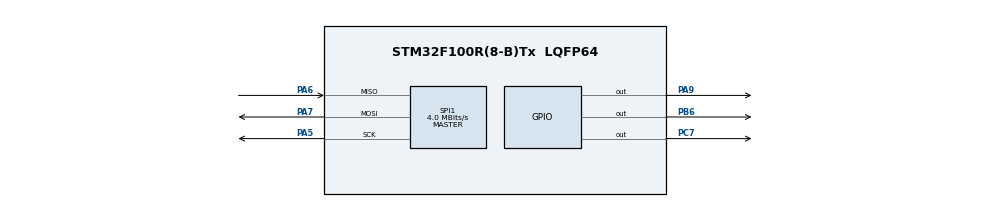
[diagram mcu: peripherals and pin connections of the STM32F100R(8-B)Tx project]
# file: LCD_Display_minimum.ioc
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Mcu.Family=STM32F1
Mcu.Name=STM32F100R(8-B)Tx
Mcu.Package=LQFP64
NVIC.PriorityGroup=NVIC_PRIORITYGROUP_4
PA13.Mode=Serial_Wire
PA13.Signal=SYS_JTMS-SWDIO
PA14.Mode=Serial_Wire
PA14.Signal=SYS_JTCK-SWCLK
PA5.Mode=Full_Duplex_Master
PA5.Signal=SPI1_SCK
PA6.Mode=Full_Duplex_Master
PA6.Signal=SPI1_MISO
PA7.Mode=Full_Duplex_Master
PA7.Signal=SPI1_MOSI
PA9.Signal=GPIO_Output
PB6.Signal=GPIO_Output
PC7.Signal=GPIO_Output
ProjectManager.HeapSize=0x200
ProjectManager.StackSize=0x400
ProjectManager.TargetToolchain=Makefile
RCC.APB1Freq_Value=8000000
RCC.APB2Freq_Value=8000000
SPI1.CalculateBaudRate=4.0 MBits/s
SPI1.Direction=SPI_DIRECTION_2LINES
SPI1.Mode=SPI_MODE_MASTER
SPI1.VirtualType=VM_MASTER
board=custom

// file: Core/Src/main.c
/* USER CODE BEGIN Header */
/**
 ******************************************************************************
 * @file           : main.c
 * @brief          : Main program body
 ******************************************************************************
 * @attention
 *
 * Copyright (c) 2025 STMicroelectronics.
 * All rights reserved.
 *
 * This software is licensed under terms that can be found in the LICENSE file
 * in the root directory of this software component.
 * If no LICENSE file comes with this software, it is provided AS-IS.
 *
 ******************************************************************************
 */
/* USER CODE END Header */
#include "main.h"

/* USER CODE BEGIN Includes */
#include "GFX_FUNCTIONS.h" /* USER CODE END Includes */
#include "ST7735.h"

/* USER CODE BEGIN PD */
// #define DCX_low()                                                              \
//   HAL_GPIO_WritePin(GPIOA, GPIO_PIN_9, GPIO_PIN_RESET) // command

// #define DCX_high()                                                             \
//   HAL_GPIO_WritePin(GPIOA, GPIO_PIN_9, GPIO_PIN_SET) // data/parameter

// #define SLEEP_OUT 0x11
// #define DISPLAY_ON 0x29

// // select at low level
// #define CSX_low() HAL_GPIO_WritePin(GPIOB, GPIO_PIN_6, GPIO_PIN_RESET)
// #define CSX_high() HAL_GPIO_WritePin(GPIOB, GPIO_PIN_6, GPIO_PIN_SET)

// // reset at low level
// #define RESX_low() HAL_GPIO_WritePin(GPIOC, GPIO_PIN_7, GPIO_PIN_RESET)
// #define RESX_high() HAL_GPIO_WritePin(GPIOC, GPIO_PIN_7, GPIO_PIN_SET)

// // pixel RGB565
// #define GREEN 0x07E0 // 0b0000011111100000
// #define RED 0xF100   // 0b1111100000000000
// #define BLUE 0x001F  // 0b0000000000011111

// #define COLMOD_CMD 0x3A
// #define COLMOD_16 0x55 // 16bits pro pixel

// #define RAMWR_CMD 0x2C // instruction before pixel data is sent

// #define MADCTL_CMD 0x36
// #define MADCTL_PARAM 0x00

// #define RASET_CMD 0x2B
// #define CASET_CMD 0x2A
// #define RASET_PARAM_START 0x0000 // Startzeile
// #define RASET_PARAM_END 0x0083   // Endzeile = 131
// #define CASET_PARAM_START 0x0000 // Startspalte
// #define CASET_PARAM_END 0x00A1   // Endspalte = 161''''
/* USER CODE END PD */

SPI_HandleTypeDef hspi1;

void SystemClock_Config(void);
static void MX_GPIO_Init(void);
static void MX_SPI1_Init(void);

/* USER CODE BEGIN 0 */
// void send_command(uint8_t command) {
//   volatile HAL_StatusTypeDef status;
//   DCX_low();
//   status = HAL_SPI_Transmit(&hspi1, &command, 1, HAL_MAX_DELAY);
//   DCX_high(); // im asnchluss kommen parmater
// }

// void send_1byte_param(uint8_t param) {
//   volatile HAL_StatusTypeDef status;
//   status = HAL_SPI_Transmit(&hspi1, &param, 1, HAL_MAX_DELAY);
// }

// uint32_t drawPixle(uint16_t color) {
//   uint32_t i;
//   uint32_t pixel = 128 * 160;
//   // Pixeldata senden (2 Bytes, Big Endian!)
//   uint8_t data[] = {color >> 8, color & 0xFF};
//   for (i = 0; i < pixel; i++) {
//     HAL_SPI_Transmit(&hspi1, data, 2, HAL_MAX_DELAY);
//   }
//   return i;
// }

/* USER CODE END 0 */

int main(void) {

  /* MCU Configuration--------------------------------------------------------*/

  /* Reset of all peripherals, Initializes the Flash interface and the Systick.
   */
  HAL_Init();

  /* Configure the system clock */
  SystemClock_Config();

  /* Initialize all configured peripherals */
  MX_GPIO_Init();
  MX_SPI1_Init();
  /* USER CODE BEGIN 2 */
  // CSX_low();
  // RESX_low();
  // HAL_Delay(50);
  // RESX_high();
  // HAL_Delay(120);
  // send_command(SLEEP_OUT); // SLP_OUT
  // HAL_Delay(120);
  // send_command(COLMOD_CMD); // COLMOD
  // send_1byte_param(COLMOD_16);
  // send_command(DISPLAY_ON);
  // HAL_Delay(20);
  // CSX_low();
  // send_command(RAMWR_CMD);
  // drawPixle(RED);
  // CSX_high();
  ST7735_Init(0);
  fillScreen(GREEN);
  /* USER CODE END 2 */

  /* Infinite loop */
  while (1) {

  }
}

void SystemClock_Config(void) {
  RCC_OscInitTypeDef RCC_OscInitStruct = {0};
  RCC_ClkInitTypeDef RCC_ClkInitStruct = {0};

  /** Initializes the RCC Oscillators according to the specified parameters
   * in the RCC_OscInitTypeDef structure.
   */
  RCC_OscInitStruct.OscillatorType = RCC_OSCILLATORTYPE_HSI;
  RCC_OscInitStruct.HSIState = RCC_HSI_ON;
  RCC_OscInitStruct.HSICalibrationValue = RCC_HSICALIBRATION_DEFAULT;
  RCC_OscInitStruct.PLL.PLLState = RCC_PLL_NONE;
  if (HAL_RCC_OscConfig(&RCC_OscInitStruct) != HAL_OK) {
    Error_Handler();
  }

  /** Initializes the CPU, AHB and APB buses clocks
   */
  RCC_ClkInitStruct.ClockType = RCC_CLOCKTYPE_HCLK | RCC_CLOCKTYPE_SYSCLK |
                                RCC_CLOCKTYPE_PCLK1 | RCC_CLOCKTYPE_PCLK2;
  RCC_ClkInitStruct.SYSCLKSource = RCC_SYSCLKSOURCE_HSI;
  RCC_ClkInitStruct.AHBCLKDivider = RCC_SYSCLK_DIV1;
  RCC_ClkInitStruct.APB1CLKDivider = RCC_HCLK_DIV1;
  RCC_ClkInitStruct.APB2CLKDivider = RCC_HCLK_DIV1;

  if (HAL_RCC_ClockConfig(&RCC_ClkInitStruct, FLASH_LATENCY_0) != HAL_OK) {
    Error_Handler();
  }
}

static void MX_SPI1_Init(void) {

  /* SPI1 parameter configuration*/
  hspi1.Instance = SPI1;
  hspi1.Init.Mode = SPI_MODE_MASTER;
  hspi1.Init.Direction = SPI_DIRECTION_2LINES;
  hspi1.Init.DataSize = SPI_DATASIZE_8BIT;
  hspi1.Init.CLKPolarity = SPI_POLARITY_LOW;
  hspi1.Init.CLKPhase = SPI_PHASE_1EDGE;
  hspi1.Init.NSS = SPI_NSS_SOFT;
  hspi1.Init.BaudRatePrescaler = SPI_BAUDRATEPRESCALER_2;
  hspi1.Init.FirstBit = SPI_FIRSTBIT_MSB;
  hspi1.Init.TIMode = SPI_TIMODE_DISABLE;
  hspi1.Init.CRCCalculation = SPI_CRCCALCULATION_DISABLE;
  hspi1.Init.CRCPolynomial = 10;
  if (HAL_SPI_Init(&hspi1) != HAL_OK) {
    Error_Handler();
  }
}

static void MX_GPIO_Init(void) {
  GPIO_InitTypeDef GPIO_InitStruct = {0};

  /* GPIO Ports Clock Enable */
  __HAL_RCC_GPIOA_CLK_ENABLE();
  __HAL_RCC_GPIOC_CLK_ENABLE();
  __HAL_RCC_GPIOB_CLK_ENABLE();

  /*Configure GPIO pin Output Level */
  HAL_GPIO_WritePin(GPIOC, GPIO_PIN_7, GPIO_PIN_RESET);

  /*Configure GPIO pin Output Level */
  HAL_GPIO_WritePin(GPIOA, GPIO_PIN_9, GPIO_PIN_RESET);

  /*Configure GPIO pin Output Level */
  HAL_GPIO_WritePin(GPIOB, GPIO_PIN_6, GPIO_PIN_RESET);

  /*Configure GPIO pin : PC7 */
  GPIO_InitStruct.Pin = GPIO_PIN_7;
  GPIO_InitStruct.Mode = GPIO_MODE_OUTPUT_PP;
  GPIO_InitStruct.Pull = GPIO_NOPULL;
  GPIO_InitStruct.Speed = GPIO_SPEED_FREQ_LOW;
  HAL_GPIO_Init(GPIOC, &GPIO_InitStruct);

  /*Configure GPIO pin : PA9 */
  GPIO_InitStruct.Pin = GPIO_PIN_9;
  GPIO_InitStruct.Mode = GPIO_MODE_OUTPUT_PP;
  GPIO_InitStruct.Pull = GPIO_NOPULL;
  GPIO_InitStruct.Speed = GPIO_SPEED_FREQ_LOW;
  HAL_GPIO_Init(GPIOA, &GPIO_InitStruct);

  /*Configure GPIO pin : PB6 */
  GPIO_InitStruct.Pin = GPIO_PIN_6;
  GPIO_InitStruct.Mode = GPIO_MODE_OUTPUT_PP;
  GPIO_InitStruct.Pull = GPIO_NOPULL;
  GPIO_InitStruct.Speed = GPIO_SPEED_FREQ_LOW;
  HAL_GPIO_Init(GPIOB, &GPIO_InitStruct);

}

void Error_Handler(void) {
  __disable_irq();
  while (1) {
  }
}

#ifdef USE_FULL_ASSERT
/**
 * @brief  Reports the name of the source file and the source line number
 *         where the assert_param error has occurred.
 * @param  file: pointer to the source file name
 * @param  line: assert_param error line source number
 * @retval None
 */
void assert_failed(uint8_t *file, uint32_t line) {
  /* USER CODE BEGIN 6 */
  /* User can add his own implementation to report the file name and line
     number, ex: printf("Wrong parameters value: file %s on line %d\r\n", file,
     line) */
  /* USER CODE END 6 */
}
#endif /* USE_FULL_ASSERT */
